# NM1500_v1 register map
File version: 1.0
Registers are 32-bit, read-write, reset 0x0 unless marked. A register's access mark holds for its fields unless they carry their own. Offsets are from the block's base; [hi:lo] are bit positions.

## EPWM0 — EPWM Register Map
Base 0x40190000
Same registers: EPWM1 0x40194000
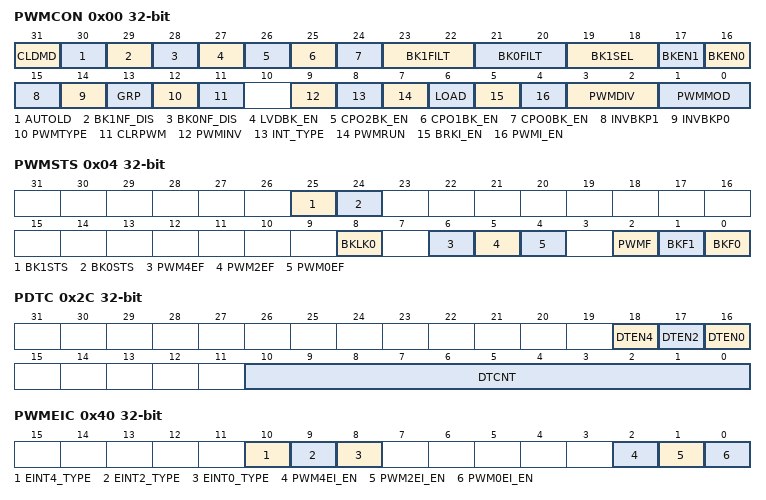
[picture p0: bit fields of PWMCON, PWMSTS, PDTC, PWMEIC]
0x00 PWMCON — EPWM Control Register
  [31] CLDMD — Center Reload Mode Enable. This bit only works when EPWM operating in Center-aligned mode.
    0=EPWM reload duty register at the period point of PWM counter; 1=EPWM reload duty register at the center point of PWM counter
  [30] AUTOLD — Auto Load Enable Bit
    0=PWM duty registers PWMx0~PWMx4 are updated by software; 1=PWM duty registers PWMx0~PWMx4 are auto-load from motor drive unit (MDU) when MDU update a set of new duty values for PWM unit
  [29] BK1NF_DIS — PWM Brake 1 Noise Filter Disable
    0=Noise filter of PWM Brake 1 Enabled; 1=Noise filter of PWM Brake 1 Disabled
  [28] BK0NF_DIS — PWM Brake 0 Noise Filter Disable
    0=Noise filter of PWM Brake 0 Enabled; 1=Noise filter of PWM Brake 0 Disabled
  [27] LVDBK_EN — Low-level Detection Trigger PWM Brake Function 1 Enable
    0=Brake Function 1 triggered by Low-level detection Disabled; 1=Brake Function 1 triggered by Low-level detection Enabled
  [26] CPO2BK_EN — CPO2 Digital Output as Brake 0 Source Enable
    0=CPO2 as one brake source in Brake 0 Disabled; 1=CPO2 as one brake source in Brake 0 Enabled
  [25] CPO1BK_EN — Enable CPO1 Digital Output as Brake 0 Source
    0=CPO1 as one brake source in Brake 0 Disabled; 1=CPO1 as one brake source in Brake 0 Enabled
  [24] CPO0BK_EN — Enable CPO0 Digital Output as Brake0 Source
    0=CPO0 as one brake source in Brake 0 Disabled; 1=CPO0 as one brake source in Brake 0 Enabled
  [23:22] BK1FILT — Brake 1 (BKPx1 pin) Edge Detector Filter Clock Selection
  [21:20] BK0FILT — Brake 0 (BKPx0 pin) Edge Detector Filter Clock Selection
  [19:18] BK1SEL — Brake Function 1 Source Selection
  [17] BKEN1 — BKPx1 Pin Trigger Brake Function Enable
    0=PWMx Brake Function 1 Disabled; 1=PWMx Brake Function 1 Enabled
  [16] BKEN0 — BKPx0 Pin Trigger Brake Function0 Enable
    0=PWMx Brake Function 0 Disabled; 1=PWMx Brake Function 0 Enabled
  [15] INVBKP1 — Inverse BKP1 State
    0=The state of pin BKPx1 is passed to the negative edge detector; 1=The inversed state of pin BKPx1 is passed to the negative edge detector
  [14] INVBKP0 — Inverse BKP0 State
    0=The state of pin BKPx0 is passed to the negative edge detector; 1=The inversed state of pin BKPx0 is passed to the negative edge detector
  [13] GRP — Group bit
    0=The signals timing of PWM0, PWM2 and PWM4 are independent; 1=Unify the signals timing of PWM0, PWM2 and PWM4 in the same phase which is controlled by PWM0
  [12] PWMTYPE — PWM Aligned Type Selection Bit.
    0=Edge-aligned type; 1=Centre-aligned type
  [11] CLRPWM — Clear PWM Counter Control Bit. Note: It is automatically cleared by hardware.
    1=Clear 16-bit PWM counter to 000H
  [9] PWMINV — Inverse PWM Comparator Output. When PWMINV is set to high the PWM comparator output signals will be inversed, therefore the PWM Duty (in percentage) is changed to (1-Duty) before PWMINV is set to high.
    0=Not inverse PWM comparator output; 1=Inverse PWM comparator output
  [8] INT_TYPE — PWM Interrupt Type Selection Bit. Note: This bit is effective when PWM is in Center-aligned mode only.
    0=PWMF will be set if PWM counter underflow; 1=PWMF will be set if PWM counter matches PWMP register
  [7] PWMRUN — Start PWMRUN Control Bit
    0=The PWM stops running; 1=The PWM counter starts running
  [6] LOAD — Reload PWM period registers (PWMP) and PWM Duty Registers (PWM0~3) Control Bit. Note2: This bit is written by software, cleared by hardware, and always read as 0.
    0=No action if written with 0. The value of PWM period register (PWMP) and PWM duty registers (PWMn0~PWMn3) are not loaded to PWM counter and Comparator registers; 1=Hardware will update the value of PWM period register (PWMP) and PWM duty registers (PWMn0~PWMn3) to PWM Counter and Comparator register at the time of PWM Counter matches PWMP in Edge- and Center-aligned modes or at the time of PWM Counter down counts with underflow in Center-aligned mode
  [5] BRKI_EN — Enable Brake0 and Brak1 Interrupt
    0=Flags BFK0 and BFK1 Disabled to trigger PWM interrupt; 1=Flags BKF0 and BKF1 Enabled to trigger PWM interrupt
  [4] PWMI_EN — Enable PWM Interrupt
    0=Flag PWMF Disabled to trigger PWM interrupt; 1=Flag PWMF Enabled to trigger PWM interrupt
  [3:2] PWMDIV — PWM Clock Pre-divider Selection
  [1:0] PWMMOD — PWM Mode Selection
0x04 PWMSTS — EPWM Status Register
  [25] BK1STS ro — Brake 1 Status (Read Only)
    0=PWM had been out of Brake 1 state; 1=PWM is in Brake 1 state
  [24] BK0STS ro — Brake 0 Status (Read Only)
    0=PWM had been out of Brake 0 state; 1=PWM is in Brake 0 state
  [8] BKLK0 — PWM Brake0 Locked. Note: This bit must be cleared by writing 1 to itself through software.
    0=Brake 0 state is released; 1=When PWM Brake detects a falling signal at BKP0, this flag will be set to high to indicate the Brake0 state is locked
  [6] PWM4EF — PWMx4 Edge Flag. Note: This bit must be cleared by writing 1 to itself through software.
    0=PWMx4 not toggled; 1=Hardware will set this flag to high at the time of PWMx4 rising or falling. If EINT4_TYPE = 0, this bit is set when PWMx4 falling is detected. If EINT4_TYPE = 1, this bit is set when PWMx4 rising is detected
  [5] PWM2EF — PWMx2 Edge Flag. Note: This bit must be cleared by writing 1 to itself through software.
    0=PWMx2 not toggled; 1=Hardware will set this flag to high at the time of PWMx2 rising or falling. If EINT2_TYPE = 0, this bit is set when PWMx2 falling is detected. If EINT2_TYPE = 1, this bit is set when PWMx2 rising is detected
  [4] PWM0EF — PWMx0 Edge Flag. Note: This bit must be cleared by writing 1 to itself through software.
    0=PWMx0 not toggled; 1=Hardware will set this flag to high at the time of PWMx0 rising or falling. If EINT0_TYPE = 0, this bit is set when PWMx0 falling is detected. If EINT0_TYPE = 1, this bit is set when PWMx0 rising is detected
  [2] PWMF — PWM Period Flag. Note: This bit must be cleared by writing 1 to itself through software.
    0=The PWM Counter has not up counted to the value of PWMP or down counted with underflow; 1=Hardware will set this flag to high at the time of PWM Counter matches PWMP in Edge- and Center-aligned modes or at the time of PWM Counter down counts with underflow in Center-aligned mode
  [1] BKF1 — PWM Brake1 Flag. Note: This bit must be cleared by writing 1 to itself through software.
    0=PWM Brake 1 is able to poll falling signal at BKP1 and has not recognized any one; 1=When PWM Brake 1 detects a falling signal at pin BKP1, this flag will be set to high
  [0] BKF0 — PWM Brake0 Flag. Note: This bit must be cleared by writing 1 to itself through software.
    0=PWM Brake 0 is able to poll falling signal at BKP0 and has not recognized any one; 1=When PWM Brake 0 detects a falling signal at BKP0, this flag will be set to high
0x08 PWMP — EPWM Period Register
  [15:0] PWMP — PWM Period Register. Edge-aligned:
0x0C PWM0 — EPWM PWM0 Duty Register
  [15:0] PWM_Duty — PWM Duty Register. Edge-aligned:
0x10 PWM2 — EPWM PWM0 Duty Register
  [15:0] PWM_Duty — PWM Duty Register. Edge-aligned:
0x14 PWM4 — EPWM PWM0 Duty Register
  [15:0] PWM_Duty — PWM Duty Register. Edge-aligned:
0x18 PMSKE — EPWM Mask Mode Enable Register
  [5:0] PMSKE — PWM Mask Enable Bit. The PWM generator signal will be masked when this bit is enabled. The corresponding PWMn channel will be output with PMD.n data.
    0=PWM generator signal is output to next stage; 1=PWM generator signal is masked and PMD.n is output to next stage
0x1C PMSKD — EPWM Mask Mode Data Register
  [5:0] PMSKD — PWM Mask Data Bit
    0=Output logic low to PWMn; 1=Output logic high to PWMn
0x2C PDTC — EPWM Dead-time Control Register
  [18] DTEN4 — Enable Dead-time Insertion for PWMx Pair (PWM4, PWM5). Dead-time insertion is only active when this pair of complementary PWM is enabled. If dead-time insertion is inactive, the outputs of pin pair are complementary without any delay.
    0=Dead-time insertion Disabled on the pin pair (PWM4, PWM5); 1=Dead-time insertion Enabled on the pin pair (PWM4, PWM5)
  [17] DTEN2 — Enable Dead-time Insertion for PWMx Pair (PWM2, PWM3). Dead-time insertion is only active when this pair of complementary PWM is enabled. If dead-time insertion is inactive, the outputs of pin pair are complementary without any delay.
    0=Dead-time insertion Disabled on the pin pair (PWM2, PWM3); 1=Dead-time insertion Enabled on the pin pair (PWM2, PWM3)
  [16] DTEN0 — Enable Dead-time Insertion for PWMx Pair (PWM0, PWM1). Dead-time insertion is only active when this pair of complementary PWM is enabled. If dead-time insertion is inactive, the outputs of pin pair are complementary without any delay.
    0=Dead-time insertion Disabled on the pin pair (PWM0, PWM1); 1=Dead-time insertion Enabled on the pin pair (PWM0, PWM1)
  [10:0] DTCNT — Dead-time Counter. The dead-time can be calculated according to the following formula:
0x30 PWMB — EPWM Brake Output
  [5:0] PWMB — PWM Brake Output. When PWM Brake is asserted, the PWM0~5 output state before polarity control will follow PWMB bit0~5 setting, respectively.
    0=PWMn output before polarity control is low when Brake is asserted; 1=PWMn output before polarity control is high when Brake is asserted
0x34 PNPC — EPWM Negative Polarity Control
  [5:0] PNPn — PWM Negative Polarity Control. The register bit controls polarity/active state of real PWM output.
    0=PWMn output is active high; 1=PWMn output is active low
0x3C PWMFCNT — EPWMF Compared Counter
  [3:0] PWMFCNT — PWMF Compared Counter. The register sets the count number which defines how many times of PWM period occurs to set bit PWMF to request the PWM period interrupt. PWMF will be set in every (1 + PWMFCNT[3:0]) time of PWM period or center point defined by INT_TYPE at PWMCON[8] occurs
0x40 PWMEIC — EPWM Edge Interrupt Control Register
  [10] EINT4_TYPE — PWMx4 Edge Interrupt Type
    0=PWM4EF will be set if falling edge is detected at PWMx4; 1=PWM4EF will be set if rising edge is detected at PWMx4
  [9] EINT2_TYPE — PWMx2 Edge Interrupt Type
    0=PWM2EF will be set if falling edge is detected at PWMx2; 1=PWM2EF will be set if rising edge is detected at PWMx2
  [8] EINT0_TYPE — PWMx0 Edge Interrupt Type
    0=PWM0EF will be set if falling edge is detected at PWMx0; 1=PWM0EF will be set if rising edge is detected at PWMx0
  [2] PWM4EI_EN — Enable PWMx4 Edge Interrupt
    0=Flag PWM4EF Disabled to trigger PWM interrupt; 1=Flag PWM4EF Enabled to trigger PWM interrupt
  [1] PWM2EI_EN — Enable PWMx2 Edge Interrupt
    0=Flag PWM2EF Disabled to trigger PWM interrupt; 1=Flag PWM2EF Enabled to trigger PWM interrupt
  [0] PWM0EI_EN — Enable PWMx0 Edge Interrupt
    0=Flag PWM0EF Disabled to trigger PWM interrupt; 1=Flag PWM0EF Enabled to trigger PWM interrupt
